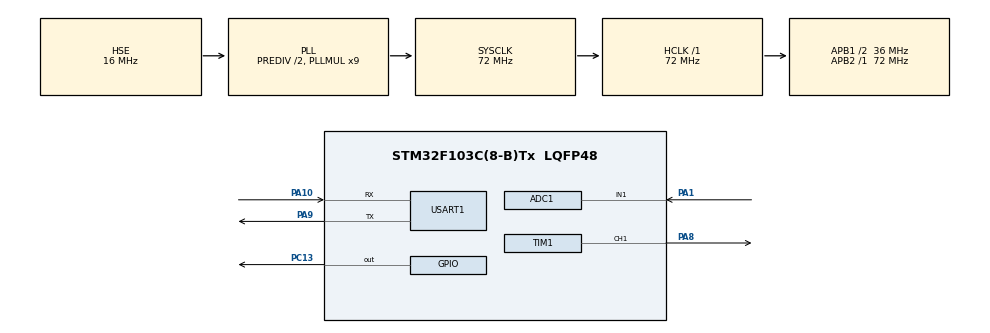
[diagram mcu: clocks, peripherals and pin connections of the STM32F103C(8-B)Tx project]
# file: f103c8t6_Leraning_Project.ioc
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ADC1.Channel-0\#ChannelRegularConversion=ADC_CHANNEL_1
ADC1.NbrOfConversion=1
ADC1.NbrOfConversionFlag=1
ADC1.Rank-0\#ChannelRegularConversion=1
ADC1.SamplingTime-0\#ChannelRegularConversion=ADC_SAMPLETIME_13CYCLES_5
ADC1.master=1
Dma.ADC1.0.Direction=DMA_PERIPH_TO_MEMORY
Dma.ADC1.0.Instance=DMA1_Channel1
Dma.ADC1.0.MemDataAlignment=DMA_MDATAALIGN_HALFWORD
Dma.ADC1.0.MemInc=DMA_MINC_ENABLE
Dma.ADC1.0.Mode=DMA_CIRCULAR
Dma.ADC1.0.PeriphDataAlignment=DMA_PDATAALIGN_HALFWORD
Dma.ADC1.0.PeriphInc=DMA_PINC_DISABLE
Dma.ADC1.0.Priority=DMA_PRIORITY_LOW
Dma.Request0=ADC1
Mcu.Family=STM32F1
Mcu.Name=STM32F103C(8-B)Tx
Mcu.Package=LQFP48
NVIC.ADC1_2_IRQn=true\:0\:0\:false\:false\:true\:true\:true\:true
NVIC.DMA1_Channel1_IRQn=true\:0\:0\:false\:false\:true\:false\:true\:true
NVIC.PriorityGroup=NVIC_PRIORITYGROUP_4
NVIC.TIM2_IRQn=true\:0\:0\:false\:false\:true\:true\:true\:true
NVIC.TIM3_IRQn=true\:0\:0\:false\:false\:true\:true\:true\:true
NVIC.USART1_IRQn=true\:0\:0\:false\:false\:true\:true\:true\:true
PA1.Signal=ADCx_IN1
PA10.Mode=Asynchronous
PA10.Signal=USART1_RX
PA13.Mode=Serial_Wire
PA13.Signal=SYS_JTMS-SWDIO
PA14.Mode=Serial_Wire
PA14.Signal=SYS_JTCK-SWCLK
PA8.Signal=S_TIM1_CH1
PA9.Mode=Asynchronous
PA9.Signal=USART1_TX
PC13-TAMPER-RTC.GPIO_PuPd=GPIO_PULLUP
PC13-TAMPER-RTC.PinState=GPIO_PIN_RESET
PC13-TAMPER-RTC.Signal=GPIO_Output
PD0-OSC_IN.Mode=HSE-External-Oscillator
PD0-OSC_IN.Signal=RCC_OSC_IN
PD1-OSC_OUT.Mode=HSE-External-Oscillator
PD1-OSC_OUT.Signal=RCC_OSC_OUT
ProjectManager.HeapSize=0x200
ProjectManager.StackSize=0x400
ProjectManager.TargetToolchain=MDK-ARM V5.32
RCC.ADCPresc=RCC_ADCPCLK2_DIV6
RCC.AHBFreq_Value=72000000
RCC.APB1CLKDivider=RCC_HCLK_DIV2
RCC.APB1Freq_Value=36000000
RCC.APB1TimFreq_Value=72000000
RCC.APB2Freq_Value=72000000
RCC.APB2TimFreq_Value=72000000
RCC.HCLKFreq_Value=72000000
RCC.HSEDivPLL=RCC_HSE_PREDIV_DIV2
RCC.HSE_VALUE=16000000
RCC.PLLMUL=RCC_PLL_MUL9
RCC.PLLSourceVirtual=RCC_PLLSOURCE_HSE
RCC.SYSCLKFreq_VALUE=72000000
RCC.SYSCLKSource=RCC_SYSCLKSOURCE_PLLCLK
RCC.USBFreq_Value=72000000
SH.ADCx_IN1.0=ADC1_IN1,IN1
SH.S_TIM1_CH1.0=TIM1_CH1,PWM Generation1 CH1
TIM1.Channel-PWM\ Generation1\ CH1=TIM_CHANNEL_1
TIM1.Period=999
TIM1.Prescaler=71
TIM1.Pulse-PWM\ Generation1\ CH1=500
TIM2.Period=99
TIM2.Prescaler=7199
TIM3.Period=2499
TIM3.Prescaler=7199
USART1.VirtualMode=VM_ASYNC
VP_TIM1_VS_ClockSourceINT.Mode=Internal
VP_TIM2_VS_ClockSourceINT.Mode=Internal
VP_TIM3_VS_ClockSourceINT.Mode=Internal
board=custom

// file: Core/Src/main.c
/* USER CODE BEGIN Header */
/**
 ******************************************************************************
 * @file           : main.c
 * @brief          : Main program body
 ******************************************************************************
 * @attention
 *
 * Copyright (c) 2026 STMicroelectronics.
 * All rights reserved.
 *
 * This software is licensed under terms that can be found in the LICENSE file
 * in the root directory of this software component.
 * If no LICENSE file comes with this software, it is provided AS-IS.
 *
 ******************************************************************************
 */
/* USER CODE END Header */
#include "main.h"
#include "adc.h"
#include "dma.h"
#include "tim.h"
#include "usart.h"
#include "gpio.h"

/* USER CODE BEGIN Includes */

#include "led.h"
#include "key.h"

/* USER CODE END Includes */

void SystemClock_Config(void);

int main(void)
{

  /* MCU Configuration--------------------------------------------------------*/

  /* Reset of all peripherals, Initializes the Flash interface and the Systick. */
  HAL_Init();

  /* Configure the system clock */
  SystemClock_Config();

  /* Initialize all configured peripherals */
  MX_GPIO_Init();
  MX_DMA_Init();
  MX_TIM3_Init();
  MX_TIM2_Init();
  MX_TIM1_Init();
  MX_USART1_UART_Init();
  MX_ADC1_Init();

  /* Infinite loop */
  /* USER CODE BEGIN WHILE */
  // 定时器中断生效使能

  // Led_Twinkle_TIM();
  // Key_Scan_TIM();

  while (1)
  {
    /* USER CODE END WHILE */

  }
}

void SystemClock_Config(void)
{
  RCC_OscInitTypeDef RCC_OscInitStruct = {0};
  RCC_ClkInitTypeDef RCC_ClkInitStruct = {0};
  RCC_PeriphCLKInitTypeDef PeriphClkInit = {0};

  /** Initializes the RCC Oscillators according to the specified parameters
  * in the RCC_OscInitTypeDef structure.
  */
  RCC_OscInitStruct.OscillatorType = RCC_OSCILLATORTYPE_HSE;
  RCC_OscInitStruct.HSEState = RCC_HSE_ON;
  RCC_OscInitStruct.HSEPredivValue = RCC_HSE_PREDIV_DIV2;
  RCC_OscInitStruct.HSIState = RCC_HSI_ON;
  RCC_OscInitStruct.PLL.PLLState = RCC_PLL_ON;
  RCC_OscInitStruct.PLL.PLLSource = RCC_PLLSOURCE_HSE;
  RCC_OscInitStruct.PLL.PLLMUL = RCC_PLL_MUL9;
  if (HAL_RCC_OscConfig(&RCC_OscInitStruct) != HAL_OK)
  {
    Error_Handler();
  }

  /** Initializes the CPU, AHB and APB buses clocks
  */
  RCC_ClkInitStruct.ClockType = RCC_CLOCKTYPE_HCLK|RCC_CLOCKTYPE_SYSCLK
                              |RCC_CLOCKTYPE_PCLK1|RCC_CLOCKTYPE_PCLK2;
  RCC_ClkInitStruct.SYSCLKSource = RCC_SYSCLKSOURCE_PLLCLK;
  RCC_ClkInitStruct.AHBCLKDivider = RCC_SYSCLK_DIV1;
  RCC_ClkInitStruct.APB1CLKDivider = RCC_HCLK_DIV2;
  RCC_ClkInitStruct.APB2CLKDivider = RCC_HCLK_DIV1;

  if (HAL_RCC_ClockConfig(&RCC_ClkInitStruct, FLASH_LATENCY_2) != HAL_OK)
  {
    Error_Handler();
  }
  PeriphClkInit.PeriphClockSelection = RCC_PERIPHCLK_ADC;
  PeriphClkInit.AdcClockSelection = RCC_ADCPCLK2_DIV6;
  if (HAL_RCCEx_PeriphCLKConfig(&PeriphClkInit) != HAL_OK)
  {
    Error_Handler();
  }
}

/* USER CODE BEGIN 4 */

void HAL_TIM_PeriodElapsedCallback(TIM_HandleTypeDef *htim)
{
  if (htim->Instance == TIM3)
  {
    LED_Twinkle_Procss();
  }

  if (htim->Instance == TIM2)
  {
    Key_Scan();
  }
}

/* USER CODE END 4 */

void Error_Handler(void)
{
  __disable_irq();
  while (1)
  {
  }
}
